# STM32L4x6 register map
File version: 2.0
CPU: CM4 r0p1, little endian, MPU, FPU, 4 interrupt priority bits
Registers are 32-bit, read-write, reset 0x0 unless marked. A register's access mark holds for its fields unless they carry their own. Offsets are from the block's base; [hi:lo] are bit positions; {n}, {i} and the like mark numbered series; 'fields as' and 'values as' point back to an identical list.

## CRS — Clock recovery system
Base 0x40006000
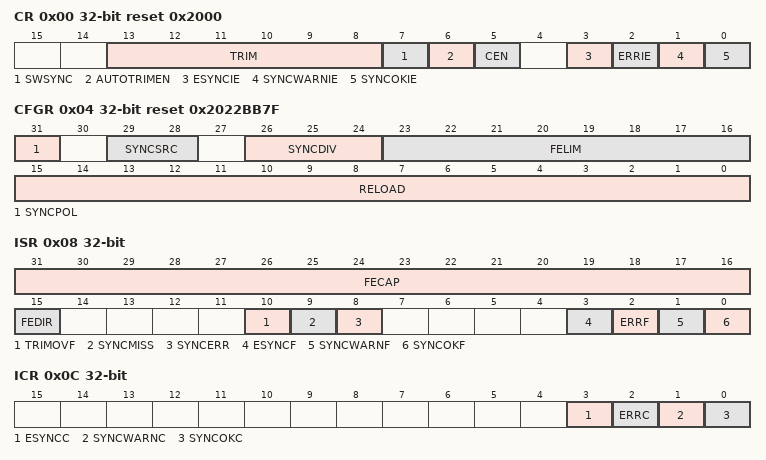
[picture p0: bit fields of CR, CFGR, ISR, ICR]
0x00 CR reset 0x2000 — control register
  [13:8] TRIM — HSI48 oscillator smooth trimming
  [7] SWSYNC — Generate software SYNC event
    1=Sync (A software sync is generated)
  [6] AUTOTRIMEN — Automatic trimming enable
    0=Disabled (Automatic trimming disabled); 1=Enabled (Automatic trimming enabled)
  [5] CEN — Frequency error counter enable
    0=Disabled (Frequency error counter disabled); 1=Enabled (Frequency error counter enabled)
  [3] ESYNCIE — Expected SYNC interrupt enable
    0=Disabled (Interrupt disabled); 1=Enabled (Interrupt enabled)
  [2] ERRIE — Synchronization or trimming error interrupt enable
    values as ESYNCIE
  [1] SYNCWARNIE — SYNC warning interrupt enable
    values as ESYNCIE
  [0] SYNCOKIE — SYNC event OK interrupt enable
    values as ESYNCIE
0x04 CFGR reset 0x2022BB7F — configuration register
  [31] SYNCPOL — SYNC polarity selection
    0=RisingEdge (SYNC active on rising edge); 1=FallingEdge (SYNC active on falling edge)
  [29:28] SYNCSRC — SYNC signal source selection
    0=GPIO_AF (GPIO AF (crs_sync_in_1) selected as SYNC signal source); 1=LSE (LSE (crs_sync_in_2) selected as SYNC signal source); 2=USB_SOF (USB SOF (crs_sync_in_3) selected as SYNC signal source)
  [26:24] SYNCDIV — SYNC divider
    0=Div1 (SYNC not divided); 1=Div2 (SYNC divided by 2); 2=Div4 (SYNC divided by 4); 3=Div8 (SYNC divided by 8); 4=Div16 (SYNC divided by 16); 5=Div32 (SYNC divided by 32); 6=Div64 (SYNC divided by 64); 7=Div128 (SYNC divided by 128)
  [23:16] FELIM — Frequency error limit
  [15:0] RELOAD — Counter reload value
0x08 ISR ro — interrupt and status register
  [31:16] FECAP — Frequency error capture
  [15] FEDIR — Frequency error direction
    0=UpCounting (Error in up-counting direction); 1=DownCounting (Error in down-counting direction)
  [10] TRIMOVF — Trimming overflow or underflow
    0=NotSignaled (Signal not set); 1=Signaled (Signal set)
  [9] SYNCMISS — SYNC missed
    0=NotSignaled (Signal not set); 1=Signaled (Signal set)
  [8] SYNCERR — SYNC error
    0=NotSignaled (Signal not set); 1=Signaled (Signal set)
  [3] ESYNCF — Expected SYNC flag
    0=NotSignaled (Signal not set); 1=Signaled (Signal set)
  [2] ERRF — Error flag
    0=NotSignaled (Signal not set); 1=Signaled (Signal set)
  [1] SYNCWARNF — SYNC warning flag
    0=NotSignaled (Signal not set); 1=Signaled (Signal set)
  [0] SYNCOKF — SYNC event OK flag
    0=NotSignaled (Signal not set); 1=Signaled (Signal set)
0x0C ICR — interrupt flag clear register
  [all] fields
    1=Clear flag
  [3] ESYNCC — Expected SYNC clear flag
  [2] ERRC — Error clear flag
  [1] SYNCWARNC — SYNC warning clear flag
  [0] SYNCOKC — SYNC event OK clear flag

## HASH — Hash processor
Base 0x50060400
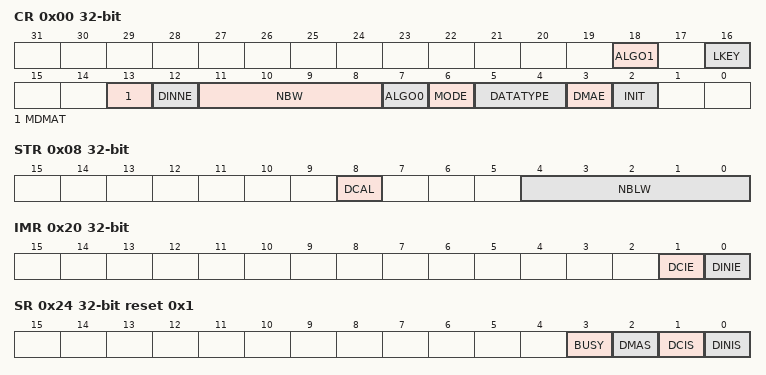
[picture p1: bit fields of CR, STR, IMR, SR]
0x00 CR access per field — control register
  [18] ALGO1 rw — ALGO
  [16] LKEY rw — Long key selection
  [13] MDMAT rw — Multiple DMA Transfers
  [12] DINNE ro — DIN not empty
  [11:8] NBW ro — Number of words already pushed
  [7] ALGO0 rw — Algorithm selection
  [6] MODE rw — Mode selection
  [5:4] DATATYPE rw — Data type selection
  [3] DMAE rw — DMA enable
  [2] INIT wo — Initialize message digest calculation
0x04 DIN — data input register
  [31:0] DATAIN — Data input
0x08 STR access per field — start register
  [8] DCAL wo — Digest calculation
  [4:0] NBLW rw — Number of valid bits in the last word of the message
{0xC+4i} HR{i} (i=0..0) ro — digest registers
  [31:0] H — H0
0x20 IMR — interrupt enable register
  [1] DCIE — Digest calculation completion interrupt enable
  [0] DINIE — Data input interrupt enable
0x24 SR access per field reset 0x1 — status register
  [3] BUSY ro — Busy bit
  [2] DMAS ro — DMA Status
  [1] DCIS rw — Digest calculation completion interrupt status
  [0] DINIS rw — Data input interrupt status
{0xF8+4i} CSR{i} (i=0..53) — context swap registers
  [31:0] CSR — CSR0
{0x310+4i} HASH_HR{i} (i=0..7) ro — HASH digest register {i}
  [31:0] H — H0
